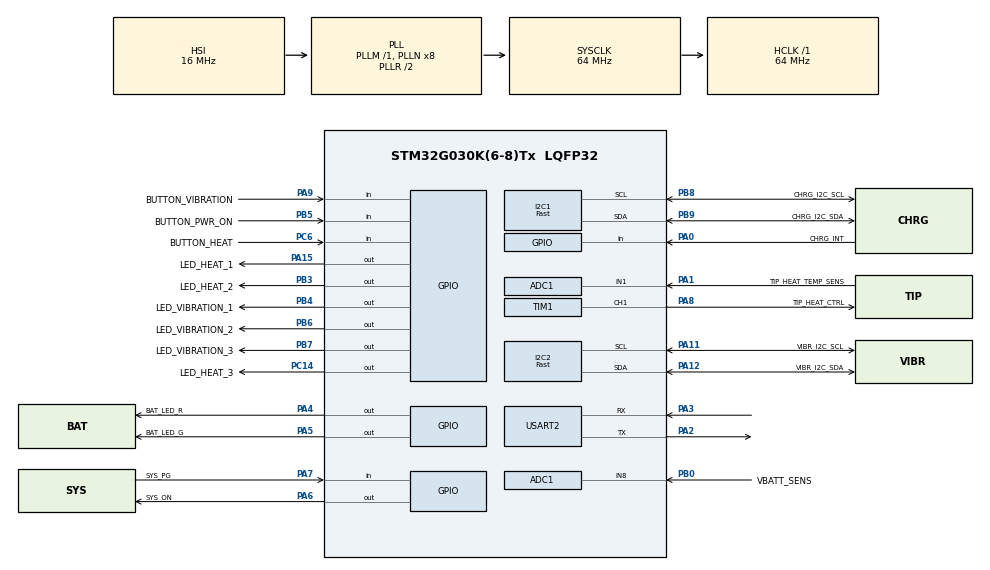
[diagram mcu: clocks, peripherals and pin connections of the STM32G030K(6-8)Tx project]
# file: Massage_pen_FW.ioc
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ADC1.Channel-1\#ChannelRegularConversion=ADC_CHANNEL_1
ADC1.Channel-2\#ChannelRegularConversion=ADC_CHANNEL_8
ADC1.ContinuousConvMode=DISABLE
ADC1.DMAContinuousRequests=ENABLE
ADC1.EnableAnalogWatchDog1=false
ADC1.NbrOfConversion=2
ADC1.NbrOfConversionFlag=1
ADC1.OversamplingMode=ENABLE
ADC1.Rank-1\#ChannelRegularConversion=1
ADC1.Rank-2\#ChannelRegularConversion=2
ADC1.Ratio=ADC_OVERSAMPLING_RATIO_16
ADC1.SamplingTime-1\#ChannelRegularConversion=ADC_SAMPLINGTIME_COMMON_1
ADC1.SamplingTime-2\#ChannelRegularConversion=ADC_SAMPLINGTIME_COMMON_1
ADC1.SamplingTimeCommon1=ADC_SAMPLETIME_160CYCLES_5
ADC1.SelectedChannel=ADC_CHANNEL_1|ADC_CHANNEL_8
ADC1.Sequencer=FULLY_CONFIGURABLE
ADC1.master=1
Dma.ADC1.0.Direction=DMA_PERIPH_TO_MEMORY
Dma.ADC1.0.EventEnable=DISABLE
Dma.ADC1.0.Instance=DMA1_Channel1
Dma.ADC1.0.MemDataAlignment=DMA_MDATAALIGN_HALFWORD
Dma.ADC1.0.MemInc=DMA_MINC_ENABLE
Dma.ADC1.0.Mode=DMA_CIRCULAR
Dma.ADC1.0.PeriphDataAlignment=DMA_PDATAALIGN_HALFWORD
Dma.ADC1.0.PeriphInc=DMA_PINC_DISABLE
Dma.ADC1.0.Polarity=HAL_DMAMUX_REQ_GEN_RISING
Dma.ADC1.0.Priority=DMA_PRIORITY_HIGH
Dma.ADC1.0.RequestNumber=1
Dma.ADC1.0.SignalID=NONE
Dma.ADC1.0.SyncEnable=DISABLE
Dma.ADC1.0.SyncPolarity=HAL_DMAMUX_SYNC_NO_EVENT
Dma.ADC1.0.SyncRequestNumber=1
Dma.ADC1.0.SyncSignalID=NONE
Dma.Request0=ADC1
I2C1.I2C_Speed_Mode=I2C_Fast
I2C1.Timing=0x00C12166
I2C2.I2C_Speed_Mode=I2C_Fast
I2C2.Timing=0x00C12166
Mcu.Family=STM32G0
Mcu.Name=STM32G030K(6-8)Tx
Mcu.Package=LQFP32
NVIC.ADC1_IRQn=true\:0\:0\:false\:false\:true\:true\:true\:true
NVIC.DMA1_Channel1_IRQn=true\:0\:0\:false\:false\:true\:false\:true\:true
NVIC.I2C1_IRQn=true\:0\:0\:false\:false\:true\:true\:true\:true
NVIC.I2C2_IRQn=true\:0\:0\:false\:false\:true\:true\:true\:true
PA0.GPIO_Label=CHRG_INT
PA0.Signal=GPIO_Input
PA1.GPIO_Label=TIP_HEAT_TEMP_SENS
PA1.Mode=IN1
PA1.Signal=ADC1_IN1
PA11\ [PA9].GPIO_Label=VIBR_I2C_SCL
PA11\ [PA9].Mode=I2C
PA11\ [PA9].Signal=I2C2_SCL
PA12\ [PA10].GPIO_Label=VIBR_I2C_SDA
PA12\ [PA10].Mode=I2C
PA12\ [PA10].Signal=I2C2_SDA
PA13.Mode=Serial_Wire
PA13.Signal=SYS_SWDIO
PA14-BOOT0.Mode=Serial_Wire
PA14-BOOT0.Signal=SYS_SWCLK
PA15.GPIO_Label=LED_HEAT_1
PA15.Signal=GPIO_Output
PA2.Mode=Asynchronous
PA2.Signal=USART2_TX
PA3.Mode=Asynchronous
PA3.Signal=USART2_RX
PA4.GPIO_Label=BAT_LED_R
PA4.Signal=GPIO_Output
PA5.GPIO_Label=BAT_LED_G
PA5.Signal=GPIO_Output
PA6.GPIO_Label=SYS_ON
PA6.Signal=GPIO_Output
PA7.GPIO_Label=SYS_PG
PA7.Signal=GPIO_Input
PA8.GPIO_Label=TIP_HEAT_CTRL
PA8.Signal=S_TIM1_CH1
PA9.GPIO_Label=BUTTON_VIBRATION
PA9.GPIO_PuPd=GPIO_PULLUP
PA9.Signal=GPIO_Input
PB0.GPIO_Label=VBATT_SENS
PB0.Mode=IN8
PB0.Signal=ADC1_IN8
PB3.GPIO_Label=LED_HEAT_2
PB3.Signal=GPIO_Output
PB4.GPIO_Label=LED_VIBRATION_1
PB4.Signal=GPIO_Output
PB5.GPIO_Label=BUTTON_PWR_ON
PB5.Signal=GPIO_Input
PB6.GPIO_Label=LED_VIBRATION_2
PB6.Signal=GPIO_Output
PB7.GPIO_Label=LED_VIBRATION_3
PB7.Signal=GPIO_Output
PB8.GPIO_Label=CHRG_I2C_SCL
PB8.Mode=I2C
PB8.Signal=I2C1_SCL
PB9.GPIO_Label=CHRG_I2C_SDA
PB9.Mode=I2C
PB9.Signal=I2C1_SDA
PC14-OSC32_IN\ (PC14).GPIO_Label=LED_HEAT_3
PC14-OSC32_IN\ (PC14).Signal=GPIO_Output
PC6.GPIO_Label=BUTTON_HEAT
PC6.GPIO_PuPd=GPIO_PULLUP
PC6.Signal=GPIO_Input
ProjectManager.HeapSize=0x200
ProjectManager.StackSize=0x400
ProjectManager.TargetToolchain=CMake
RCC.ADCFreq_Value=64000000
RCC.AHBFreq_Value=64000000
RCC.CortexFreq_Value=64000000
RCC.EXTERNAL_CLOCK_VALUE=12288000
RCC.HCLKFreq_Value=64000000
RCC.HSE_VALUE=8000000
RCC.HSI_VALUE=16000000
RCC.LSE_VALUE=32768
RCC.SYSCLKFreq_VALUE=64000000
RCC.SYSCLKSource=RCC_SYSCLKSOURCE_PLLCLK
RCC.VCOOutputFreq_Value=128000000
RCC.VDD_VALUE=2.5
SH.S_TIM1_CH1.0=TIM1_CH1,PWM Generation1 CH1
TIM1.AutoReloadPreload=TIM_AUTORELOAD_PRELOAD_ENABLE
TIM1.Channel-PWM\ Generation1\ CH1=TIM_CHANNEL_1
TIM1.OCPolarity_1=TIM_OCPOLARITY_HIGH
TIM1.Period=999
TIM1.Prescaler=31
USART2.VirtualMode-Asynchronous=VM_ASYNC
board=custom

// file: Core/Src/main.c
/* USER CODE BEGIN Header */
/**
  ******************************************************************************
  * @file           : main.c
  * @brief          : Main program body
  ******************************************************************************
  * @attention
  *
  * Copyright (c) 2026 STMicroelectronics.
  * All rights reserved.
  *
  * This software is licensed under terms that can be found in the LICENSE file
  * in the root directory of this software component.
  * If no LICENSE file comes with this software, it is provided AS-IS.
  *
  ******************************************************************************
  */
/* USER CODE END Header */
#include "main.h"

/* USER CODE BEGIN Includes */
#include "runtime.h"

/* USER CODE END Includes */

ADC_HandleTypeDef hadc1;
DMA_HandleTypeDef hdma_adc1;

I2C_HandleTypeDef hi2c1;
I2C_HandleTypeDef hi2c2;

TIM_HandleTypeDef htim1;

UART_HandleTypeDef huart2;

void SystemClock_Config(void);
static void MX_GPIO_Init(void);
static void MX_DMA_Init(void);
static void MX_ADC1_Init(void);
static void MX_I2C1_Init(void);
static void MX_I2C2_Init(void);
static void MX_TIM1_Init(void);
static void MX_USART2_UART_Init(void);

int main(void)
{

  /* MCU Configuration--------------------------------------------------------*/

  /* Reset of all peripherals, Initializes the Flash interface and the Systick. */
  HAL_Init();

  /* Configure the system clock */
  SystemClock_Config();

  /* Initialize all configured peripherals */
  MX_GPIO_Init();
  MX_DMA_Init();
  MX_ADC1_Init();
  MX_I2C1_Init();
  MX_I2C2_Init();
  MX_TIM1_Init();
  MX_USART2_UART_Init();
  /* USER CODE BEGIN 2 */
  Runtime_Init(&hadc1, &hi2c1, &hi2c2, &htim1, NULL);
  /* USER CODE END 2 */

  /* Infinite loop */
  while (1)
  {

    /* USER CODE BEGIN 3 */
    Runtime_Poll();
  }
  /* USER CODE END 3 */
}

void SystemClock_Config(void)
{
  RCC_OscInitTypeDef RCC_OscInitStruct = {0};
  RCC_ClkInitTypeDef RCC_ClkInitStruct = {0};

  /** Configure the main internal regulator output voltage
  */
  HAL_PWREx_ControlVoltageScaling(PWR_REGULATOR_VOLTAGE_SCALE1);

  /** Initializes the RCC Oscillators according to the specified parameters
  * in the RCC_OscInitTypeDef structure.
  */
  RCC_OscInitStruct.OscillatorType = RCC_OSCILLATORTYPE_HSI;
  RCC_OscInitStruct.HSIState = RCC_HSI_ON;
  RCC_OscInitStruct.HSIDiv = RCC_HSI_DIV1;
  RCC_OscInitStruct.HSICalibrationValue = RCC_HSICALIBRATION_DEFAULT;
  RCC_OscInitStruct.PLL.PLLState = RCC_PLL_ON;
  RCC_OscInitStruct.PLL.PLLSource = RCC_PLLSOURCE_HSI;
  RCC_OscInitStruct.PLL.PLLM = RCC_PLLM_DIV1;
  RCC_OscInitStruct.PLL.PLLN = 8;
  RCC_OscInitStruct.PLL.PLLP = RCC_PLLP_DIV2;
  RCC_OscInitStruct.PLL.PLLR = RCC_PLLR_DIV2;
  if (HAL_RCC_OscConfig(&RCC_OscInitStruct) != HAL_OK)
  {
    Error_Handler();
  }

  /** Initializes the CPU, AHB and APB buses clocks
  */
  RCC_ClkInitStruct.ClockType = RCC_CLOCKTYPE_HCLK|RCC_CLOCKTYPE_SYSCLK
                              |RCC_CLOCKTYPE_PCLK1;
  RCC_ClkInitStruct.SYSCLKSource = RCC_SYSCLKSOURCE_PLLCLK;
  RCC_ClkInitStruct.AHBCLKDivider = RCC_SYSCLK_DIV1;
  RCC_ClkInitStruct.APB1CLKDivider = RCC_HCLK_DIV1;

  if (HAL_RCC_ClockConfig(&RCC_ClkInitStruct, FLASH_LATENCY_2) != HAL_OK)
  {
    Error_Handler();
  }
}

static void MX_ADC1_Init(void)
{

  ADC_ChannelConfTypeDef sConfig = {0};

  /** Configure the global features of the ADC (Clock, Resolution, Data Alignment and number of conversion)
  */
  hadc1.Instance = ADC1;
  hadc1.Init.ClockPrescaler = ADC_CLOCK_SYNC_PCLK_DIV2;
  hadc1.Init.Resolution = ADC_RESOLUTION_12B;
  hadc1.Init.DataAlign = ADC_DATAALIGN_RIGHT;
  hadc1.Init.ScanConvMode = ADC_SCAN_ENABLE;
  hadc1.Init.EOCSelection = ADC_EOC_SINGLE_CONV;
  hadc1.Init.LowPowerAutoWait = DISABLE;
  hadc1.Init.LowPowerAutoPowerOff = DISABLE;
  hadc1.Init.ContinuousConvMode = DISABLE;
  hadc1.Init.NbrOfConversion = 2;
  hadc1.Init.DiscontinuousConvMode = DISABLE;
  hadc1.Init.ExternalTrigConv = ADC_SOFTWARE_START;
  hadc1.Init.ExternalTrigConvEdge = ADC_EXTERNALTRIGCONVEDGE_NONE;
  hadc1.Init.DMAContinuousRequests = ENABLE;
  hadc1.Init.Overrun = ADC_OVR_DATA_PRESERVED;
  hadc1.Init.SamplingTimeCommon1 = ADC_SAMPLETIME_160CYCLES_5;
  hadc1.Init.SamplingTimeCommon2 = ADC_SAMPLETIME_1CYCLE_5;
  hadc1.Init.OversamplingMode = ENABLE;
  hadc1.Init.Oversampling.Ratio = ADC_OVERSAMPLING_RATIO_16;
  hadc1.Init.Oversampling.RightBitShift = ADC_RIGHTBITSHIFT_NONE;
  hadc1.Init.Oversampling.TriggeredMode = ADC_TRIGGEREDMODE_SINGLE_TRIGGER;
  hadc1.Init.TriggerFrequencyMode = ADC_TRIGGER_FREQ_HIGH;
  if (HAL_ADC_Init(&hadc1) != HAL_OK)
  {
    Error_Handler();
  }

  /** Configure Regular Channel
  */
  sConfig.Channel = ADC_CHANNEL_1;
  sConfig.Rank = ADC_REGULAR_RANK_1;
  sConfig.SamplingTime = ADC_SAMPLINGTIME_COMMON_1;
  if (HAL_ADC_ConfigChannel(&hadc1, &sConfig) != HAL_OK)
  {
    Error_Handler();
  }

  /** Configure Regular Channel
  */
  sConfig.Channel = ADC_CHANNEL_8;
  sConfig.Rank = ADC_REGULAR_RANK_2;
  if (HAL_ADC_ConfigChannel(&hadc1, &sConfig) != HAL_OK)
  {
    Error_Handler();
  }

}

static void MX_I2C1_Init(void)
{

  hi2c1.Instance = I2C1;
  hi2c1.Init.Timing = 0x00C12166;
  hi2c1.Init.OwnAddress1 = 0;
  hi2c1.Init.AddressingMode = I2C_ADDRESSINGMODE_7BIT;
  hi2c1.Init.DualAddressMode = I2C_DUALADDRESS_DISABLE;
  hi2c1.Init.OwnAddress2 = 0;
  hi2c1.Init.OwnAddress2Masks = I2C_OA2_NOMASK;
  hi2c1.Init.GeneralCallMode = I2C_GENERALCALL_DISABLE;
  hi2c1.Init.NoStretchMode = I2C_NOSTRETCH_DISABLE;
  if (HAL_I2C_Init(&hi2c1) != HAL_OK)
  {
    Error_Handler();
  }

  /** Configure Analogue filter
  */
  if (HAL_I2CEx_ConfigAnalogFilter(&hi2c1, I2C_ANALOGFILTER_ENABLE) != HAL_OK)
  {
    Error_Handler();
  }

  /** Configure Digital filter
  */
  if (HAL_I2CEx_ConfigDigitalFilter(&hi2c1, 0) != HAL_OK)
  {
    Error_Handler();
  }

}

static void MX_I2C2_Init(void)
{

  hi2c2.Instance = I2C2;
  hi2c2.Init.Timing = 0x00C12166;
  hi2c2.Init.OwnAddress1 = 0;
  hi2c2.Init.AddressingMode = I2C_ADDRESSINGMODE_7BIT;
  hi2c2.Init.DualAddressMode = I2C_DUALADDRESS_DISABLE;
  hi2c2.Init.OwnAddress2 = 0;
  hi2c2.Init.OwnAddress2Masks = I2C_OA2_NOMASK;
  hi2c2.Init.GeneralCallMode = I2C_GENERALCALL_DISABLE;
  hi2c2.Init.NoStretchMode = I2C_NOSTRETCH_DISABLE;
  if (HAL_I2C_Init(&hi2c2) != HAL_OK)
  {
    Error_Handler();
  }

  /** Configure Analogue filter
  */
  if (HAL_I2CEx_ConfigAnalogFilter(&hi2c2, I2C_ANALOGFILTER_ENABLE) != HAL_OK)
  {
    Error_Handler();
  }

  /** Configure Digital filter
  */
  if (HAL_I2CEx_ConfigDigitalFilter(&hi2c2, 0) != HAL_OK)
  {
    Error_Handler();
  }

}

static void MX_TIM1_Init(void)
{

  TIM_MasterConfigTypeDef sMasterConfig = {0};
  TIM_OC_InitTypeDef sConfigOC = {0};
  TIM_BreakDeadTimeConfigTypeDef sBreakDeadTimeConfig = {0};

  htim1.Instance = TIM1;
  htim1.Init.Prescaler = 31;
  htim1.Init.CounterMode = TIM_COUNTERMODE_UP;
  htim1.Init.Period = 999;
  htim1.Init.ClockDivision = TIM_CLOCKDIVISION_DIV1;
  htim1.Init.RepetitionCounter = 0;
  htim1.Init.AutoReloadPreload = TIM_AUTORELOAD_PRELOAD_ENABLE;
  if (HAL_TIM_PWM_Init(&htim1) != HAL_OK)
  {
    Error_Handler();
  }
  sMasterConfig.MasterOutputTrigger = TIM_TRGO_RESET;
  sMasterConfig.MasterOutputTrigger2 = TIM_TRGO2_RESET;
  sMasterConfig.MasterSlaveMode = TIM_MASTERSLAVEMODE_DISABLE;
  if (HAL_TIMEx_MasterConfigSynchronization(&htim1, &sMasterConfig) != HAL_OK)
  {
    Error_Handler();
  }
  sConfigOC.OCMode = TIM_OCMODE_PWM1;
  sConfigOC.Pulse = 0;
  sConfigOC.OCPolarity = TIM_OCPOLARITY_HIGH;
  sConfigOC.OCNPolarity = TIM_OCNPOLARITY_HIGH;
  sConfigOC.OCFastMode = TIM_OCFAST_DISABLE;
  sConfigOC.OCIdleState = TIM_OCIDLESTATE_RESET;
  sConfigOC.OCNIdleState = TIM_OCNIDLESTATE_RESET;
  if (HAL_TIM_PWM_ConfigChannel(&htim1, &sConfigOC, TIM_CHANNEL_1) != HAL_OK)
  {
    Error_Handler();
  }
  sBreakDeadTimeConfig.OffStateRunMode = TIM_OSSR_DISABLE;
  sBreakDeadTimeConfig.OffStateIDLEMode = TIM_OSSI_DISABLE;
  sBreakDeadTimeConfig.LockLevel = TIM_LOCKLEVEL_OFF;
  sBreakDeadTimeConfig.DeadTime = 0;
  sBreakDeadTimeConfig.BreakState = TIM_BREAK_DISABLE;
  sBreakDeadTimeConfig.BreakPolarity = TIM_BREAKPOLARITY_HIGH;
  sBreakDeadTimeConfig.BreakFilter = 0;
  sBreakDeadTimeConfig.BreakAFMode = TIM_BREAK_AFMODE_INPUT;
  sBreakDeadTimeConfig.Break2State = TIM_BREAK2_DISABLE;
  sBreakDeadTimeConfig.Break2Polarity = TIM_BREAK2POLARITY_HIGH;
  sBreakDeadTimeConfig.Break2Filter = 0;
  sBreakDeadTimeConfig.Break2AFMode = TIM_BREAK_AFMODE_INPUT;
  sBreakDeadTimeConfig.AutomaticOutput = TIM_AUTOMATICOUTPUT_DISABLE;
  if (HAL_TIMEx_ConfigBreakDeadTime(&htim1, &sBreakDeadTimeConfig) != HAL_OK)
  {
    Error_Handler();
  }
  HAL_TIM_MspPostInit(&htim1);

}

static void MX_USART2_UART_Init(void)
{

  huart2.Instance = USART2;
  huart2.Init.BaudRate = 115200;
  huart2.Init.WordLength = UART_WORDLENGTH_8B;
  huart2.Init.StopBits = UART_STOPBITS_1;
  huart2.Init.Parity = UART_PARITY_NONE;
  huart2.Init.Mode = UART_MODE_TX_RX;
  huart2.Init.HwFlowCtl = UART_HWCONTROL_NONE;
  huart2.Init.OverSampling = UART_OVERSAMPLING_16;
  huart2.Init.OneBitSampling = UART_ONE_BIT_SAMPLE_DISABLE;
  huart2.Init.ClockPrescaler = UART_PRESCALER_DIV1;
  huart2.AdvancedInit.AdvFeatureInit = UART_ADVFEATURE_NO_INIT;
  if (HAL_UART_Init(&huart2) != HAL_OK)
  {
    Error_Handler();
  }

}

static void MX_DMA_Init(void)
{

  /* DMA controller clock enable */
  __HAL_RCC_DMA1_CLK_ENABLE();

  /* DMA interrupt init */
  /* DMA1_Channel1_IRQn interrupt configuration */
  HAL_NVIC_SetPriority(DMA1_Channel1_IRQn, 0, 0);
  HAL_NVIC_EnableIRQ(DMA1_Channel1_IRQn);

}

static void MX_GPIO_Init(void)
{
  GPIO_InitTypeDef GPIO_InitStruct = {0};

  /* GPIO Ports Clock Enable */
  __HAL_RCC_GPIOB_CLK_ENABLE();
  __HAL_RCC_GPIOC_CLK_ENABLE();
  __HAL_RCC_GPIOA_CLK_ENABLE();

  /*Configure GPIO pin Output Level */
  HAL_GPIO_WritePin(LED_HEAT_3_GPIO_Port, LED_HEAT_3_Pin, GPIO_PIN_RESET);

  /*Configure GPIO pin Output Level */
  HAL_GPIO_WritePin(GPIOA, BAT_LED_R_Pin|BAT_LED_G_Pin|SYS_ON_Pin|LED_HEAT_1_Pin, GPIO_PIN_RESET);

  /*Configure GPIO pin Output Level */
  HAL_GPIO_WritePin(GPIOB, LED_HEAT_2_Pin|LED_VIBRATION_1_Pin|LED_VIBRATION_2_Pin|LED_VIBRATION_3_Pin, GPIO_PIN_RESET);

  /*Configure GPIO pin : LED_HEAT_3_Pin */
  GPIO_InitStruct.Pin = LED_HEAT_3_Pin;
  GPIO_InitStruct.Mode = GPIO_MODE_OUTPUT_PP;
  GPIO_InitStruct.Pull = GPIO_NOPULL;
  GPIO_InitStruct.Speed = GPIO_SPEED_FREQ_LOW;
  HAL_GPIO_Init(LED_HEAT_3_GPIO_Port, &GPIO_InitStruct);

  /*Configure GPIO pins : CHRG_INT_Pin SYS_PG_Pin */
  GPIO_InitStruct.Pin = CHRG_INT_Pin|SYS_PG_Pin;
  GPIO_InitStruct.Mode = GPIO_MODE_INPUT;
  GPIO_InitStruct.Pull = GPIO_NOPULL;
  HAL_GPIO_Init(GPIOA, &GPIO_InitStruct);

  /*Configure GPIO pins : BAT_LED_R_Pin BAT_LED_G_Pin SYS_ON_Pin LED_HEAT_1_Pin */
  GPIO_InitStruct.Pin = BAT_LED_R_Pin|BAT_LED_G_Pin|SYS_ON_Pin|LED_HEAT_1_Pin;
  GPIO_InitStruct.Mode = GPIO_MODE_OUTPUT_PP;
  GPIO_InitStruct.Pull = GPIO_NOPULL;
  GPIO_InitStruct.Speed = GPIO_SPEED_FREQ_LOW;
  HAL_GPIO_Init(GPIOA, &GPIO_InitStruct);

  /*Configure GPIO pin : BUTTON_VIBRATION_Pin */
  GPIO_InitStruct.Pin = BUTTON_VIBRATION_Pin;
  GPIO_InitStruct.Mode = GPIO_MODE_INPUT;
  GPIO_InitStruct.Pull = GPIO_PULLUP;
  HAL_GPIO_Init(BUTTON_VIBRATION_GPIO_Port, &GPIO_InitStruct);

  /*Configure GPIO pin : BUTTON_HEAT_Pin */
  GPIO_InitStruct.Pin = BUTTON_HEAT_Pin;
  GPIO_InitStruct.Mode = GPIO_MODE_INPUT;
  GPIO_InitStruct.Pull = GPIO_PULLUP;
  HAL_GPIO_Init(BUTTON_HEAT_GPIO_Port, &GPIO_InitStruct);

  /*Configure GPIO pins : LED_HEAT_2_Pin LED_VIBRATION_1_Pin LED_VIBRATION_2_Pin LED_VIBRATION_3_Pin */
  GPIO_InitStruct.Pin = LED_HEAT_2_Pin|LED_VIBRATION_1_Pin|LED_VIBRATION_2_Pin|LED_VIBRATION_3_Pin;
  GPIO_InitStruct.Mode = GPIO_MODE_OUTPUT_PP;
  GPIO_InitStruct.Pull = GPIO_NOPULL;
  GPIO_InitStruct.Speed = GPIO_SPEED_FREQ_LOW;
  HAL_GPIO_Init(GPIOB, &GPIO_InitStruct);

  /*Configure GPIO pin : BUTTON_PWR_ON_Pin */
  GPIO_InitStruct.Pin = BUTTON_PWR_ON_Pin;
  GPIO_InitStruct.Mode = GPIO_MODE_INPUT;
  GPIO_InitStruct.Pull = GPIO_NOPULL;
  HAL_GPIO_Init(BUTTON_PWR_ON_GPIO_Port, &GPIO_InitStruct);

}

void Error_Handler(void)
{
  __disable_irq();
  while (1)
  {
  }
}
